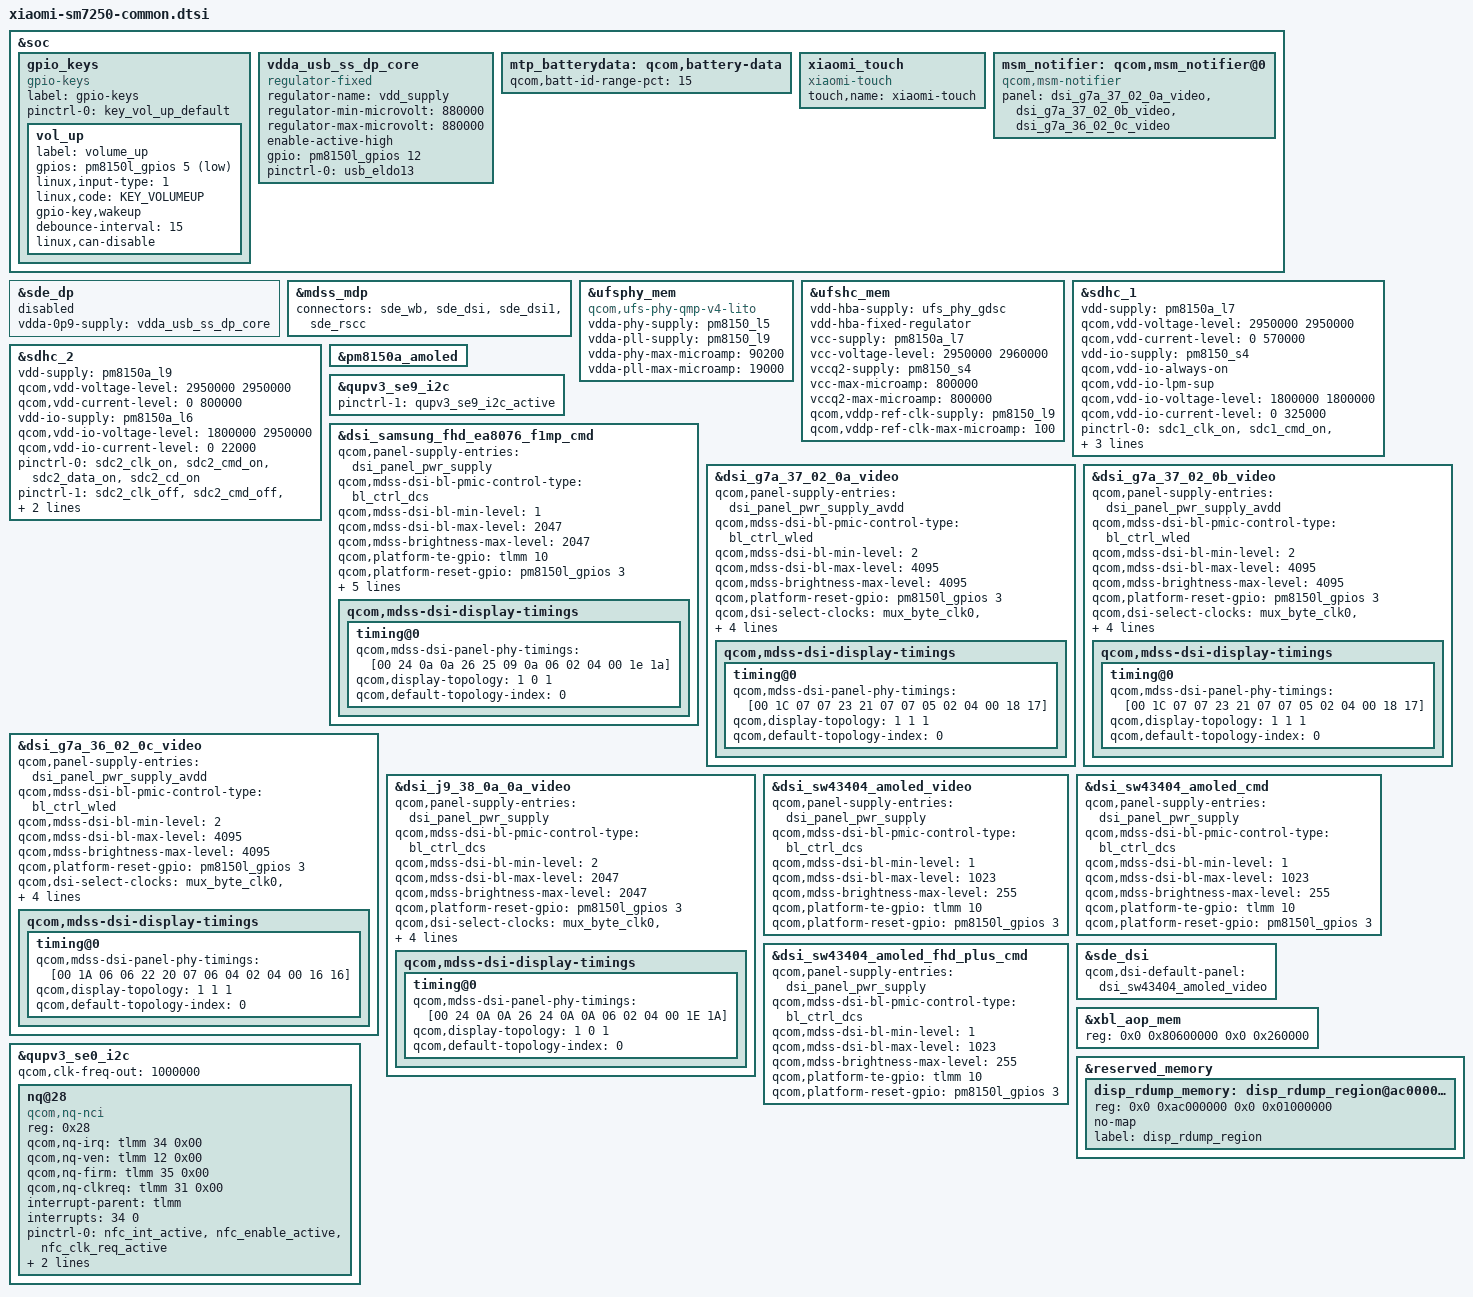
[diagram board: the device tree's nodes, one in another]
#include <dt-bindings/gpio/gpio.h>
#include <dt-bindings/clock/qcom,aop-qmp.h>
#include <dt-bindings/clock/qcom,camcc-lito.h>
#include <dt-bindings/clock/qcom,dispcc-lito.h>
#include <dt-bindings/clock/qcom,gcc-lito.h>
#include <dt-bindings/clock/qcom,gpucc-lito.h>
#include <dt-bindings/clock/qcom,npucc-lito.h>
#include <dt-bindings/clock/qcom,rpmh.h>
#include <dt-bindings/clock/qcom,videocc-lito.h>
#include <dt-bindings/interrupt-controller/arm-gic.h>
#include <dt-bindings/msm/msm-bus-ids.h>
#include <dt-bindings/regulator/qcom,rpmh-regulator-levels.h>
#include <dt-bindings/soc/qcom,ipcc.h>
#include <dt-bindings/soc/qcom,rpmh-rsc.h>
#include <dt-bindings/spmi/spmi.h>

#include "lito-audio-overlay.dtsi"
#include "lito-pmic-overlay.dtsi"
#include "lito-sde-display.dtsi"
#include "dsi-panel-samsung-fhd-ea8076-f1-cmd.dtsi"
#include "dsi-panel-g7a-37-02-0a-dsc-video.dtsi"
#include "dsi-panel-g7a-37-02-0b-dsc-video.dtsi"
#include "dsi-panel-g7a-36-02-0c-dsc-video.dtsi"
#include "dsi-panel-j9-38-0a-0a-fhd-video.dtsi"
#include "lito-thermal-overlay.dtsi"

&soc {
	gpio_keys {
		compatible = "gpio-keys";
		label = "gpio-keys";

		pinctrl-names = "default";
		pinctrl-0 = <&key_vol_up_default>;

		vol_up {
			label = "volume_up";
			gpios = <&pm8150l_gpios 5 GPIO_ACTIVE_LOW>;
			linux,input-type = <1>;
			linux,code = <KEY_VOLUMEUP>;
			gpio-key,wakeup;
			debounce-interval = <15>;
			linux,can-disable;
		};
	};

	vdda_usb_ss_dp_core: vdda_usb_ss_dp_core {
		compatible = "regulator-fixed";
		regulator-name = "vdd_supply";
		regulator-min-microvolt = <880000>;
		regulator-max-microvolt = <880000>;
		enable-active-high;
		gpio = <&pm8150l_gpios 12 GPIO_ACTIVE_HIGH>;
		pinctrl-names = "default";
		pinctrl-0 = <&usb_eldo13>;
	};

	mtp_batterydata: qcom,battery-data {
		qcom,batt-id-range-pct = <15>;
		#include "qg-batterydata-alium-3600mah.dtsi"
		#include "qg-batterydata-atl466271_3300mAh.dtsi"
	};

	xiaomi_touch {
		compatible = "xiaomi-touch";
		status = "ok";
		touch,name = "xiaomi-touch";
	};

	msm_notifier: qcom,msm_notifier@0 {
		compatible = "qcom,msm-notifier";
		panel = <&dsi_g7a_37_02_0a_video &dsi_g7a_37_02_0b_video &dsi_g7a_36_02_0c_video>;
	};
};

&sde_dp {
	status = "disabled";
	vdda-0p9-supply = <&vdda_usb_ss_dp_core>;
};

&mdss_mdp {
	connectors = <&sde_wb &sde_dsi &sde_dsi1 &sde_rscc>;
};

&ufsphy_mem {
	compatible = "qcom,ufs-phy-qmp-v4-lito";

	vdda-phy-supply = <&pm8150_l5>;
	vdda-pll-supply = <&pm8150_l9>;
	vdda-phy-max-microamp = <90200>;
	vdda-pll-max-microamp = <19000>;

	status = "ok";
};

&ufshc_mem {
	vdd-hba-supply = <&ufs_phy_gdsc>;
	vdd-hba-fixed-regulator;
	vcc-supply = <&pm8150a_l7>;
	vcc-voltage-level = <2950000 2960000>;
	vccq2-supply = <&pm8150_s4>;
	vcc-max-microamp = <800000>;
	vccq2-max-microamp = <800000>;

	qcom,vddp-ref-clk-supply = <&pm8150_l9>;
	qcom,vddp-ref-clk-max-microamp = <100>;

	status = "ok";
};

&sdhc_1 {
	vdd-supply = <&pm8150a_l7>;
	qcom,vdd-voltage-level = <2950000 2950000>;
	qcom,vdd-current-level = <0 570000>;

	vdd-io-supply = <&pm8150_s4>;
	qcom,vdd-io-always-on;
	qcom,vdd-io-lpm-sup;
	qcom,vdd-io-voltage-level = <1800000 1800000>;
	qcom,vdd-io-current-level = <0 325000>;

	pinctrl-names = "active", "sleep";
	pinctrl-0 = <&sdc1_clk_on &sdc1_cmd_on &sdc1_data_on
					&sdc1_rclk_on>;
	pinctrl-1 = <&sdc1_clk_off &sdc1_cmd_off &sdc1_data_off
					&sdc1_rclk_off>;

	status = "ok";
};

&sdhc_2 {
	vdd-supply = <&pm8150a_l9>;
	qcom,vdd-voltage-level = <2950000 2950000>;
	qcom,vdd-current-level = <0 800000>;

	vdd-io-supply = <&pm8150a_l6>;
	qcom,vdd-io-voltage-level = <1800000 2950000>;
	qcom,vdd-io-current-level = <0 22000>;

	pinctrl-names = "active", "sleep";
	pinctrl-0 = <&sdc2_clk_on  &sdc2_cmd_on &sdc2_data_on &sdc2_cd_on>;
	pinctrl-1 = <&sdc2_clk_off &sdc2_cmd_off &sdc2_data_off &sdc2_cd_off>;

	cd-gpios = <&tlmm 69 GPIO_ACTIVE_LOW>;

	status = "ok";
};

&pm8150a_amoled {
	status = "ok";
};

&qupv3_se9_i2c {
	/* Override sleep state of pins */
	pinctrl-1 = <&qupv3_se9_i2c_active>;
};

&dsi_samsung_fhd_ea8076_f1mp_cmd {
		qcom,panel-supply-entries = <&dsi_panel_pwr_supply>;
		qcom,mdss-dsi-bl-pmic-control-type = "bl_ctrl_dcs";
		qcom,mdss-dsi-bl-min-level = <1>;
		qcom,mdss-dsi-bl-max-level = <2047>;
		qcom,mdss-brightness-max-level = <2047>;
		qcom,platform-te-gpio = <&tlmm 10 0>;
		qcom,platform-reset-gpio = <&pm8150l_gpios 3 0>;

		qcom,dsi-select-clocks = "mux_byte_clk0", "mux_pixel_clk0",
			"src_byte_clk0", "src_pixel_clk0",
			"shadow_byte_clk0", "shadow_pixel_clk0";

		qcom,ulps-enabled;
		qcom,mdss-dsi-display-timings {
		timing@0 {
			qcom,mdss-dsi-panel-phy-timings = [00 24 0a 0a 26 25 09
				0a 06 02 04 00 1e 1a];
			qcom,display-topology = <1 0 1>;
			qcom,default-topology-index = <0>;
		};
	};
};

&dsi_g7a_37_02_0a_video {
		qcom,panel-supply-entries = <&dsi_panel_pwr_supply_avdd>;
		qcom,mdss-dsi-bl-pmic-control-type = "bl_ctrl_wled";
		qcom,mdss-dsi-bl-min-level = <2>;
		qcom,mdss-dsi-bl-max-level = <4095>;
		qcom,mdss-brightness-max-level = <4095>;
		qcom,platform-reset-gpio = <&pm8150l_gpios 3 0>;

		qcom,dsi-select-clocks = "mux_byte_clk0", "mux_pixel_clk0",
			"src_byte_clk0", "src_pixel_clk0",
			"shadow_byte_clk0", "shadow_pixel_clk0";

		qcom,ulps-enabled;
		qcom,mdss-dsi-display-timings {
		timing@0 {
			qcom,mdss-dsi-panel-phy-timings = [00 1C 07 07 23 21 07
				07 05 02 04 00 18 17];
			qcom,display-topology = <1 1 1>;
			qcom,default-topology-index = <0>;
		};
	};
};

&dsi_g7a_37_02_0b_video {
		qcom,panel-supply-entries = <&dsi_panel_pwr_supply_avdd>;
		qcom,mdss-dsi-bl-pmic-control-type = "bl_ctrl_wled";
		qcom,mdss-dsi-bl-min-level = <2>;
		qcom,mdss-dsi-bl-max-level = <4095>;
		qcom,mdss-brightness-max-level = <4095>;
		qcom,platform-reset-gpio = <&pm8150l_gpios 3 0>;

		qcom,dsi-select-clocks = "mux_byte_clk0", "mux_pixel_clk0",
			"src_byte_clk0", "src_pixel_clk0",
			"shadow_byte_clk0", "shadow_pixel_clk0";

		qcom,ulps-enabled;
		qcom,mdss-dsi-display-timings {
		timing@0 {
			qcom,mdss-dsi-panel-phy-timings = [00 1C 07 07 23 21 07
				07 05 02 04 00 18 17];
			qcom,display-topology = <1 1 1>;
			qcom,default-topology-index = <0>;
		};
	};
};

&dsi_g7a_36_02_0c_video {
		qcom,panel-supply-entries = <&dsi_panel_pwr_supply_avdd>;
		qcom,mdss-dsi-bl-pmic-control-type = "bl_ctrl_wled";
		qcom,mdss-dsi-bl-min-level = <2>;
		qcom,mdss-dsi-bl-max-level = <4095>;
		qcom,mdss-brightness-max-level = <4095>;
		qcom,platform-reset-gpio = <&pm8150l_gpios 3 0>;

		qcom,dsi-select-clocks = "mux_byte_clk0", "mux_pixel_clk0",
			"src_byte_clk0", "src_pixel_clk0",
			"shadow_byte_clk0", "shadow_pixel_clk0";

		qcom,ulps-enabled;
		qcom,mdss-dsi-display-timings {
		timing@0 {
			qcom,mdss-dsi-panel-phy-timings = [00 1A 06 06 22 20 07
				06 04 02 04 00 16 16];
			qcom,display-topology = <1 1 1>;
			qcom,default-topology-index = <0>;
		};
	};

};

&dsi_j9_38_0a_0a_video {
		qcom,panel-supply-entries = <&dsi_panel_pwr_supply>;
		qcom,mdss-dsi-bl-pmic-control-type = "bl_ctrl_dcs";
		qcom,mdss-dsi-bl-min-level = <2>;
		qcom,mdss-dsi-bl-max-level = <2047>;
		qcom,mdss-brightness-max-level = <2047>;
		qcom,platform-reset-gpio = <&pm8150l_gpios 3 0>;

		qcom,dsi-select-clocks = "mux_byte_clk0", "mux_pixel_clk0",
			"src_byte_clk0", "src_pixel_clk0",
			"shadow_byte_clk0", "shadow_pixel_clk0";

		qcom,ulps-enabled;
		qcom,mdss-dsi-display-timings {
		timing@0 {
			qcom,mdss-dsi-panel-phy-timings = [00 24 0A 0A 26 24 0A
				0A 06 02 04 00 1E 1A];
			qcom,display-topology = <1 0 1>;
			qcom,default-topology-index = <0>;
		};
	};
};

&dsi_sw43404_amoled_video {
	/delete-property/ qcom,esd-check-enabled;

	qcom,panel-supply-entries = <&dsi_panel_pwr_supply>;
	qcom,mdss-dsi-bl-pmic-control-type = "bl_ctrl_dcs";
	qcom,mdss-dsi-bl-min-level = <1>;
	qcom,mdss-dsi-bl-max-level = <1023>;
	qcom,mdss-brightness-max-level = <255>;
	qcom,platform-te-gpio = <&tlmm 10 0>;
	qcom,platform-reset-gpio = <&pm8150l_gpios 3 0>;
};

&dsi_sw43404_amoled_cmd {
	qcom,panel-supply-entries = <&dsi_panel_pwr_supply>;
	qcom,mdss-dsi-bl-pmic-control-type = "bl_ctrl_dcs";
	qcom,mdss-dsi-bl-min-level = <1>;
	qcom,mdss-dsi-bl-max-level = <1023>;
	qcom,mdss-brightness-max-level = <255>;
	qcom,platform-te-gpio = <&tlmm 10 0>;
	qcom,platform-reset-gpio = <&pm8150l_gpios 3 0>;
};

&dsi_sw43404_amoled_fhd_plus_cmd {
	qcom,panel-supply-entries = <&dsi_panel_pwr_supply>;
	qcom,mdss-dsi-bl-pmic-control-type = "bl_ctrl_dcs";
	qcom,mdss-dsi-bl-min-level = <1>;
	qcom,mdss-dsi-bl-max-level = <1023>;
	qcom,mdss-brightness-max-level = <255>;
	qcom,platform-te-gpio = <&tlmm 10 0>;
	qcom,platform-reset-gpio = <&pm8150l_gpios 3 0>;
};

&sde_dsi {
	qcom,dsi-default-panel = <&dsi_sw43404_amoled_video>;
};

&xbl_aop_mem {
	reg = <0x0 0x80600000 0x0 0x260000>;
};

&reserved_memory {
	disp_rdump_memory: disp_rdump_region@ac000000 {
		reg = <0x0 0xac000000 0x0 0x01000000>;
		no-map;
		label = "disp_rdump_region";
	};
};

&qupv3_se0_i2c {
	status = "ok";
	qcom,clk-freq-out = <1000000>;
	#address-cells = <1>;
	#size-cells = <0>;
	nq@28 {
		compatible = "qcom,nq-nci";
		reg = <0x28>;
		qcom,nq-irq = <&tlmm 34 0x00>;
		qcom,nq-ven = <&tlmm 12 0x00>;
		qcom,nq-firm = <&tlmm 35 0x00>;
		qcom,nq-clkreq = <&tlmm 31 0x00>;
		interrupt-parent = <&tlmm>;
		interrupts = <34 0>;
		interrupt-names = "nfc_irq";
		pinctrl-names = "nfc_active", "nfc_suspend";
		pinctrl-0 = <&nfc_int_active &nfc_enable_active
				&nfc_clk_req_active>;
		pinctrl-1 = <&nfc_int_suspend &nfc_enable_suspend
				&nfc_clk_req_suspend>;
	};
};
